# STM32F0x8 register map
File version: 1.3
CPU: CM0 r0p0, little endian, no MPU, no FPU, 2 interrupt priority bits
Registers are 32-bit, read-write, reset 0x0 unless marked. A register's access mark holds for its fields unless they carry their own. Offsets are from the block's base; [hi:lo] are bit positions; {n}, {i} and the like mark numbered series; 'fields as' and 'values as' point back to an identical list.

## RCC — Reset and clock control
Base 0x40021000
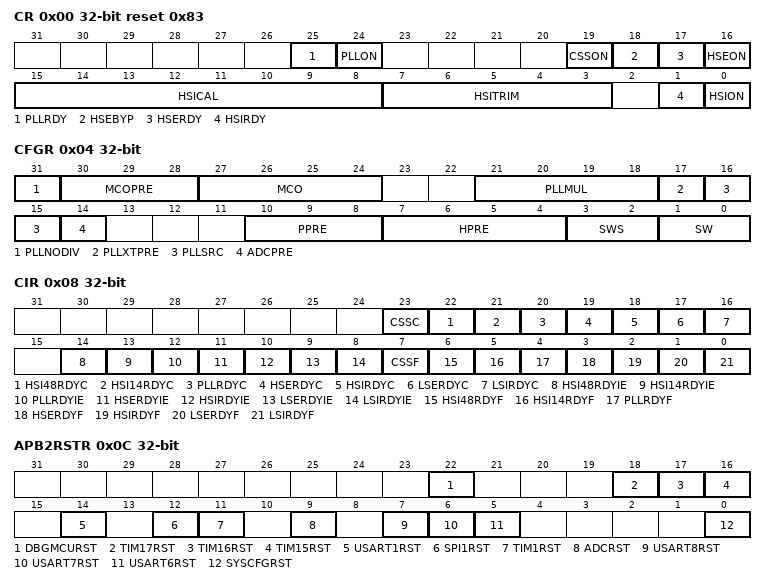
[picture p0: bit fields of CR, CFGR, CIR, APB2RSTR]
0x00 CR access per field reset 0x83 — Clock control register
  [25] PLLRDY ro — PLL clock ready flag
    0=NotReady (Clock not ready); 1=Ready (Clock ready)
  [24] PLLON rw — PLL enable
    0=Off (Clock Off); 1=On (Clock On)
  [19] CSSON rw — Clock Security System enable
    0=Off (Clock security system disabled (clock detector OFF)); 1=On (Clock security system enable (clock detector ON if the HSE is ready, OFF if not))
  [18] HSEBYP rw — External High Speed clock Bypass
    0=NotBypassed (HSE crystal oscillator not bypassed); 1=Bypassed (HSE crystal oscillator bypassed with external clock)
  [17] HSERDY ro — External High Speed clock ready flag
    0=NotReady (Clock not ready); 1=Ready (Clock ready)
  [16] HSEON rw — External High Speed clock enable
    0=Off (Clock Off); 1=On (Clock On)
  [15:8] HSICAL ro — Internal High Speed clock Calibration
  [7:3] HSITRIM rw — Internal High Speed clock trimming
  [1] HSIRDY ro — Internal High Speed clock ready flag
    0=NotReady (Clock not ready); 1=Ready (Clock ready)
  [0] HSION rw — Internal High Speed clock enable
    0=Off (Clock Off); 1=On (Clock On)
0x04 CFGR access per field — Clock configuration register (RCC_CFGR)
  [31] PLLNODIV rw — PLL clock not divided for MCO
    0=Div2 (PLL is divided by 2 for MCO); 1=Div1 (PLL is not divided for MCO)
  [30:28] MCOPRE rw — Microcontroller Clock Output Prescaler
    0=Div1 (MCO is divided by 1); 1=Div2 (MCO is divided by 2); 2=Div4 (MCO is divided by 4); 3=Div8 (MCO is divided by 8); 4=Div16 (MCO is divided by 16); 5=Div32 (MCO is divided by 32); 6=Div64 (MCO is divided by 64); 7=Div128 (MCO is divided by 128)
  [27:24] MCO rw — Microcontroller clock output
    0=NoMCO (MCO output disabled, no clock on MCO); 1=HSI14 (Internal RC 14 MHz (HSI14) oscillator clock selected); 2=LSI (Internal low speed (LSI) oscillator clock selected); 3=LSE (External low speed (LSE) oscillator clock selected); 4=SYSCLK (System clock selected); 5=HSI (Internal RC 8 MHz (HSI) oscillator clock selected); 6=HSE (External 4-32 MHz (HSE) oscillator clock selected); 7=PLL (PLL clock selected (divided by 1 or 2, depending en PLLNODIV)); 8=HSI48 (Internal RC 48 MHz (HSI48) oscillator clock selected)
  [21:18] PLLMUL rw — PLL Multiplication Factor
    {v}=Mul{v+2} (PLL input clock x{v+2}) (v=0..14); 15=Mul16x (PLL input clock x16)
  [17] PLLXTPRE rw — HSE divider for PLL entry. Same bit as PREDIC[0] from CFGR2 register. Refer to it for its meaning
    0=Div1 (HSE clock not divided); 1=Div2 (HSE clock divided by 2)
  [16:15] PLLSRC rw — PLL input clock source
    0=HSI_Div2 (HSI divided by 2 selected as PLL input clock); 1=HSI_Div_PREDIV (HSI divided by PREDIV selected as PLL input clock); 2=HSE_Div_PREDIV (HSE divided by PREDIV selected as PLL input clock); 3=HSI48_Div_PREDIV (HSI48 divided by PREDIV selected as PLL input clock)
  [14] ADCPRE rw — ADCPRE is deprecated. See ADC field in CFGR2 register.
  [10:8] PPRE rw — APB Low speed prescaler (APB1)
    4=Div2 (HCLK divided by 2); 5=Div4 (HCLK divided by 4); 6=Div8 (HCLK divided by 8); 7=Div16 (HCLK divided by 16); other=Div1 (HCLK not divided)
  [7:4] HPRE rw — AHB prescaler
    8=Div2 (SYSCLK divided by 2); 9=Div4 (SYSCLK divided by 4); 10=Div8 (SYSCLK divided by 8); 11=Div16 (SYSCLK divided by 16); 12=Div64 (SYSCLK divided by 64); 13=Div128 (SYSCLK divided by 128); 14=Div256 (SYSCLK divided by 256); 15=Div512 (SYSCLK divided by 512); other=Div1 (SYSCLK not divided)
  [3:2] SWS ro — System Clock Switch Status
    0=HSI (HSI oscillator used as system clock); 1=HSE (HSE oscillator used as system clock); 2=PLL (PLL used as system clock); 3=HSI48 (HSI48 used as system clock (when avaiable))
  [1:0] SW rw — System clock Switch
    0=HSI (HSI selected as system clock); 1=HSE (HSE selected as system clock); 2=PLL (PLL selected as system clock); 3=HSI48 (HSI48 selected as system clock (when available))
0x08 CIR access per field — Clock interrupt register (RCC_CIR)
  [23] CSSC wo — Clock security system interrupt clear
    1=Clear CSSF flag
  [22] HSI48RDYC wo — HSI48 Ready Interrupt Clear
    1=Clear interrupt flag
  [21] HSI14RDYC wo — HSI 14 MHz Ready Interrupt Clear
    1=Clear interrupt flag
  [20] PLLRDYC wo — PLL Ready Interrupt Clear
    1=Clear interrupt flag
  [19] HSERDYC wo — HSE Ready Interrupt Clear
    1=Clear interrupt flag
  [18] HSIRDYC wo — HSI Ready Interrupt Clear
    1=Clear interrupt flag
  [17] LSERDYC wo — LSE Ready Interrupt Clear
    1=Clear interrupt flag
  [16] LSIRDYC wo — LSI Ready Interrupt Clear
    1=Clear interrupt flag
  [14] HSI48RDYIE rw — HSI48 ready interrupt enable
    0=Disabled (Interrupt disabled); 1=Enabled (Interrupt enabled)
  [13] HSI14RDYIE rw — HSI14 ready interrupt enable
    values as HSI48RDYIE
  [12] PLLRDYIE rw — PLL Ready Interrupt Enable
    values as HSI48RDYIE
  [11] HSERDYIE rw — HSE Ready Interrupt Enable
    values as HSI48RDYIE
  [10] HSIRDYIE rw — HSI Ready Interrupt Enable
    values as HSI48RDYIE
  [9] LSERDYIE rw — LSE Ready Interrupt Enable
    values as HSI48RDYIE
  [8] LSIRDYIE rw — LSI Ready Interrupt Enable
    values as HSI48RDYIE
  [7] CSSF ro — Clock Security System Interrupt flag
    0=NotInterrupted (No clock security interrupt caused by HSE clock failure); 1=Interrupted (Clock security interrupt caused by HSE clock failure)
  [6] HSI48RDYF ro — HSI48 ready interrupt flag
    0=NotInterrupted (No clock ready interrupt); 1=Interrupted (Clock ready interrupt)
  [5] HSI14RDYF ro — HSI14 ready interrupt flag
    values as HSI48RDYF
  [4] PLLRDYF ro — PLL Ready Interrupt flag
    values as HSI48RDYF
  [3] HSERDYF ro — HSE Ready Interrupt flag
    values as HSI48RDYF
  [2] HSIRDYF ro — HSI Ready Interrupt flag
    values as HSI48RDYF
  [1] LSERDYF ro — LSE Ready Interrupt flag
    values as HSI48RDYF
  [0] LSIRDYF ro — LSI Ready Interrupt flag
    values as HSI48RDYF
0x0C APB2RSTR — APB2 peripheral reset register (RCC_APB2RSTR)
  [all] fields
    1=Reset the selected module
  [22] DBGMCURST — Debug MCU reset
  [18] TIM17RST — TIM17 timer reset
  [17] TIM16RST — TIM16 timer reset
  [16] TIM15RST — TIM15 timer reset
  [14] USART1RST — USART1 reset
  [12] SPI1RST — SPI 1 reset
  [11] TIM1RST — TIM1 timer reset
  [9] ADCRST — ADC interface reset
  [7] USART8RST — USART8 reset
  [6] USART7RST — USART7 reset
  [5] USART6RST — USART6 reset
  [0] SYSCFGRST — SYSCFG and COMP reset
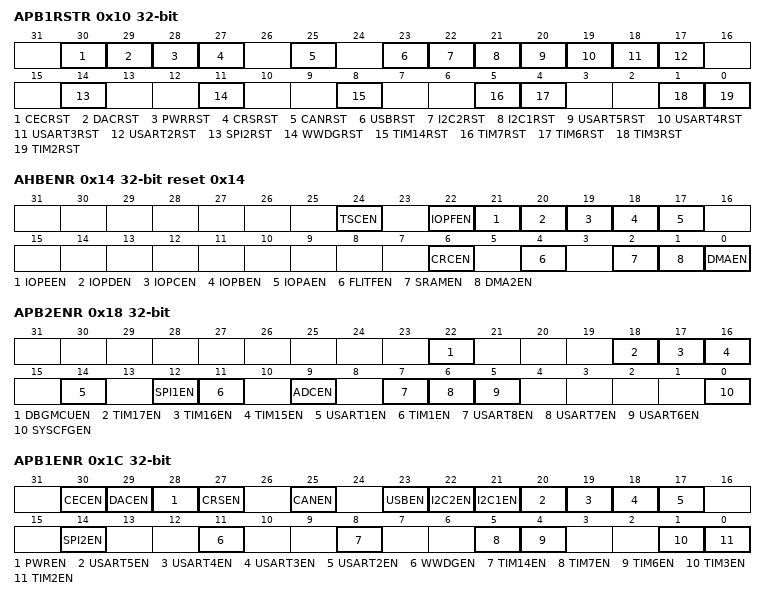
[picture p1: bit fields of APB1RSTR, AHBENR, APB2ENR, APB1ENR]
0x10 APB1RSTR — APB1 peripheral reset register (RCC_APB1RSTR)
  [all] fields
    1=Reset the selected module
  [30] CECRST — HDMI CEC reset
  [29] DACRST — DAC interface reset
  [28] PWRRST — Power interface reset
  [27] CRSRST — Clock Recovery System interface reset
  [25] CANRST — CAN interface reset
  [23] USBRST — USB interface reset
  [22] I2C2RST — I2C2 reset
  [21] I2C1RST — I2C1 reset
  [20] USART5RST — USART5 reset
  [19] USART4RST — USART4 reset
  [18] USART3RST — USART3 reset
  [17] USART2RST — USART 2 reset
  [14] SPI2RST — SPI2 reset
  [11] WWDGRST — Window watchdog reset
  [8] TIM14RST — Timer 14 reset
  [5] TIM7RST — TIM7 timer reset
  [4] TIM6RST — Timer 6 reset
  [1] TIM3RST — Timer 3 reset
  [0] TIM2RST — Timer 2 reset
0x14 AHBENR reset 0x14 — AHB Peripheral Clock enable register (RCC_AHBENR)
  [all] fields
    0=Disabled (The selected clock is disabled); 1=Enabled (The selected clock is enabled)
  [24] TSCEN — Touch sensing controller clock enable
  [22] IOPFEN — I/O port F clock enable
  [21] IOPEEN — I/O port E clock enable
  [20] IOPDEN — I/O port D clock enable
  [19] IOPCEN — I/O port C clock enable
  [18] IOPBEN — I/O port B clock enable
  [17] IOPAEN — I/O port A clock enable
  [6] CRCEN — CRC clock enable
  [4] FLITFEN — FLITF clock enable
  [2] SRAMEN — SRAM interface clock enable
  [1] DMA2EN — DMA2 clock enable
  [0] DMAEN — DMA clock enable
0x18 APB2ENR — APB2 peripheral clock enable register (RCC_APB2ENR)
  [all] fields
    values as the fields of AHBENR
  [22] DBGMCUEN — MCU debug module clock enable
  [18] TIM17EN — TIM17 timer clock enable
  [17] TIM16EN — TIM16 timer clock enable
  [16] TIM15EN — TIM15 timer clock enable
  [14] USART1EN — USART1 clock enable
  [12] SPI1EN — SPI 1 clock enable
  [11] TIM1EN — TIM1 Timer clock enable
  [9] ADCEN — ADC 1 interface clock enable
  [7] USART8EN — USART8 clock enable
  [6] USART7EN — USART7 clock enable
  [5] USART6EN — USART6 clock enable
  [0] SYSCFGEN — SYSCFG clock enable
0x1C APB1ENR — APB1 peripheral clock enable register (RCC_APB1ENR)
  [all] fields
    values as the fields of AHBENR
  [30] CECEN — HDMI CEC interface clock enable
  [29] DACEN — DAC interface clock enable
  [28] PWREN — Power interface clock enable
  [27] CRSEN — Clock Recovery System interface clock enable
  [25] CANEN — CAN interface clock enable
  [23] USBEN — USB interface clock enable
  [22] I2C2EN — I2C 2 clock enable
  [21] I2C1EN — I2C 1 clock enable
  [20] USART5EN — USART5 clock enable
  [19] USART4EN — USART4 clock enable
  [18] USART3EN — USART3 clock enable
  [17] USART2EN — USART 2 clock enable
  [14] SPI2EN — SPI 2 clock enable
  [11] WWDGEN — Window watchdog clock enable
  [8] TIM14EN — Timer 14 clock enable
  [5] TIM7EN — TIM7 timer clock enable
  [4] TIM6EN — Timer 6 clock enable
  [1] TIM3EN — Timer 3 clock enable
  [0] TIM2EN — Timer 2 clock enable
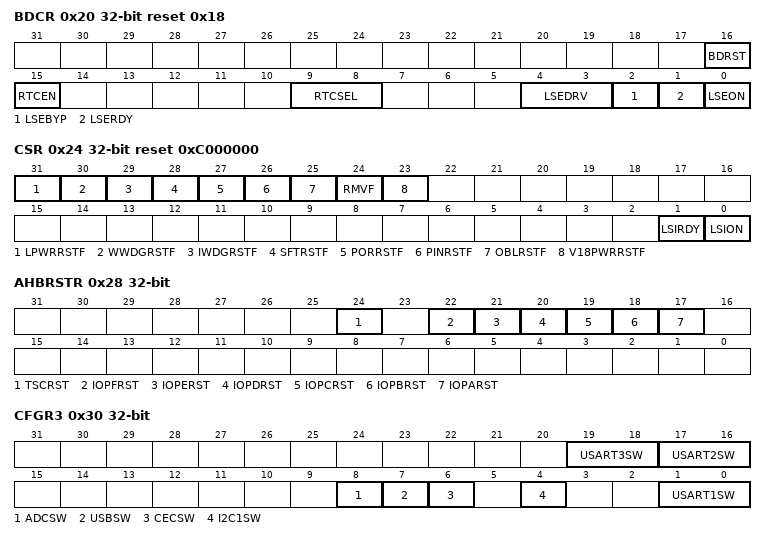
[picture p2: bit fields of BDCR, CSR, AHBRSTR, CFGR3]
0x20 BDCR access per field reset 0x18 — Backup domain control register (RCC_BDCR)
  [16] BDRST rw — Backup domain software reset
    0=Disabled (Reset not activated); 1=Enabled (Reset the entire RTC domain)
  [15] RTCEN rw — RTC clock enable
    0=Disabled (RTC clock disabled); 1=Enabled (RTC clock enabled)
  [9:8] RTCSEL rw — RTC clock source selection
    0=NoClock; 1=LSE (LSE oscillator clock used as RTC clock); 2=LSI (LSI oscillator clock used as RTC clock); 3=HSE (HSE oscillator clock divided by a prescaler used as RTC clock)
  [4:3] LSEDRV rw — LSE oscillator drive capability
    0=Low (Low drive capacity); 1=Medium-high drive capacity; 2=Medium-low drive capacity; 3=High drive capacity
  [2] LSEBYP rw — External Low Speed oscillator bypass
    0=NotBypassed (LSE crystal oscillator not bypassed); 1=Bypassed (LSE crystal oscillator bypassed with external clock)
  [1] LSERDY ro — External Low Speed oscillator ready
    0=NotReady (LSE oscillator not ready); 1=Ready (LSE oscillator ready)
  [0] LSEON rw — External Low Speed oscillator enable
    0=Off (LSE oscillator Off); 1=On (LSE oscillator On)
0x24 CSR access per field reset 0xC000000 — Control/status register (RCC_CSR)
  [31] LPWRRSTF rw — Low-power reset flag
    on read: 0=No reset has occured; 1=Reset (A reset has occured)
  [30] WWDGRSTF rw — Window watchdog reset flag
    values as LPWRRSTF
  [29] IWDGRSTF rw — Independent watchdog reset flag
    values as LPWRRSTF
  [28] SFTRSTF rw — Software reset flag
    values as LPWRRSTF
  [27] PORRSTF rw — POR/PDR reset flag
    values as LPWRRSTF
  [26] PINRSTF rw — PIN reset flag
    values as LPWRRSTF
  [25] OBLRSTF rw — Option byte loader reset flag
    values as LPWRRSTF
  [24] RMVF rw — Remove reset flag
    on write: 1=Clears the reset flag
  [23] V18PWRRSTF rw — 1.8 V domain reset flag
    values as LPWRRSTF
  [1] LSIRDY ro — Internal low speed oscillator ready
    0=NotReady (LSI oscillator not ready); 1=Ready (LSI oscillator ready)
  [0] LSION rw — Internal low speed oscillator enable
    0=Off (LSI oscillator Off); 1=On (LSI oscillator On)
0x28 AHBRSTR — AHB peripheral reset register
  [all] fields
    1=Reset the selected module
  [24] TSCRST — Touch sensing controller reset
  [22] IOPFRST — I/O port F reset
  [21] IOPERST — I/O port E reset
  [20] IOPDRST — I/O port D reset
  [19] IOPCRST — I/O port C reset
  [18] IOPBRST — I/O port B reset
  [17] IOPARST — I/O port A reset
0x2C CFGR2 — Clock configuration register 2
  [3:0] PREDIV — PREDIV division factor
    0=Div1 (PREDIV input clock not divided); {v}=Div{v+1} (PREDIV input clock divided by {v+1}) (v=1..15)
0x30 CFGR3 — Clock configuration register 3
  [19:18] USART3SW — USART3 clock source
    0=PCLK (PCLK selected as USART clock source); 1=SYSCLK (SYSCLK selected as USART clock source); 2=LSE (LSE selected as USART clock source); 3=HSI (HSI selected as USART clock source)
  [17:16] USART2SW — USART2 clock source selection
    values as USART3SW
  [8] ADCSW — ADCSW is deprecated. See ADC field in CFGR2 register.
  [7] USBSW — USB clock source selection
    0=HSI48 (HSI48 selected as USB clock source); 1=PLLCLK (PLL clock selected as USB clock source)
  [6] CECSW — HDMI CEC clock source selection
    0=HSI_Div244 (HSI clock divided by 244 selected as CEC clock source); 1=LSE (LSE clock selected as CEC clock source)
  [4] I2C1SW — I2C1 clock source selection
    0=HSI (HSI clock selected as I2C clock source); 1=SYSCLK (SYSCLK clock selected as I2C clock source)
  [1:0] USART1SW — USART1 clock source selection
    values as USART3SW
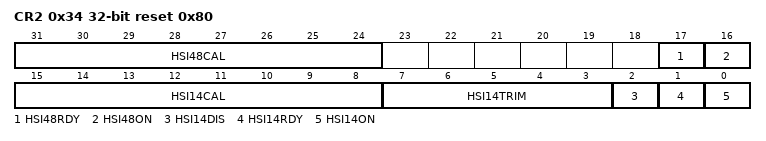
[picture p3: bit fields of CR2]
0x34 CR2 access per field reset 0x80 — Clock control register 2
  [31:24] HSI48CAL ro — HSI48 factory clock calibration
  [17] HSI48RDY ro — HSI48 clock ready flag
    0=NotReady (HSI48 oscillator ready); 1=Ready (HSI48 oscillator ready)
  [16] HSI48ON rw — HSI48 clock enable
    0=Off (HSI48 oscillator off); 1=On (HSI48 oscillator on)
  [15:8] HSI14CAL ro — HSI14 clock calibration
  [7:3] HSI14TRIM rw — HSI14 clock trimming
  [2] HSI14DIS rw — HSI14 clock request from ADC disable
    0=Allow (ADC can turn on the HSI14 oscillator); 1=Disallow (ADC can not turn on the HSI14 oscillator)
  [1] HSI14RDY ro — HR14 clock ready flag
    0=NotReady (HSI14 oscillator not ready); 1=Ready (HSI14 oscillator ready)
  [0] HSI14ON rw — HSI14 clock enable
    0=Off (HSI14 oscillator off); 1=On (HSI14 oscillator on)
